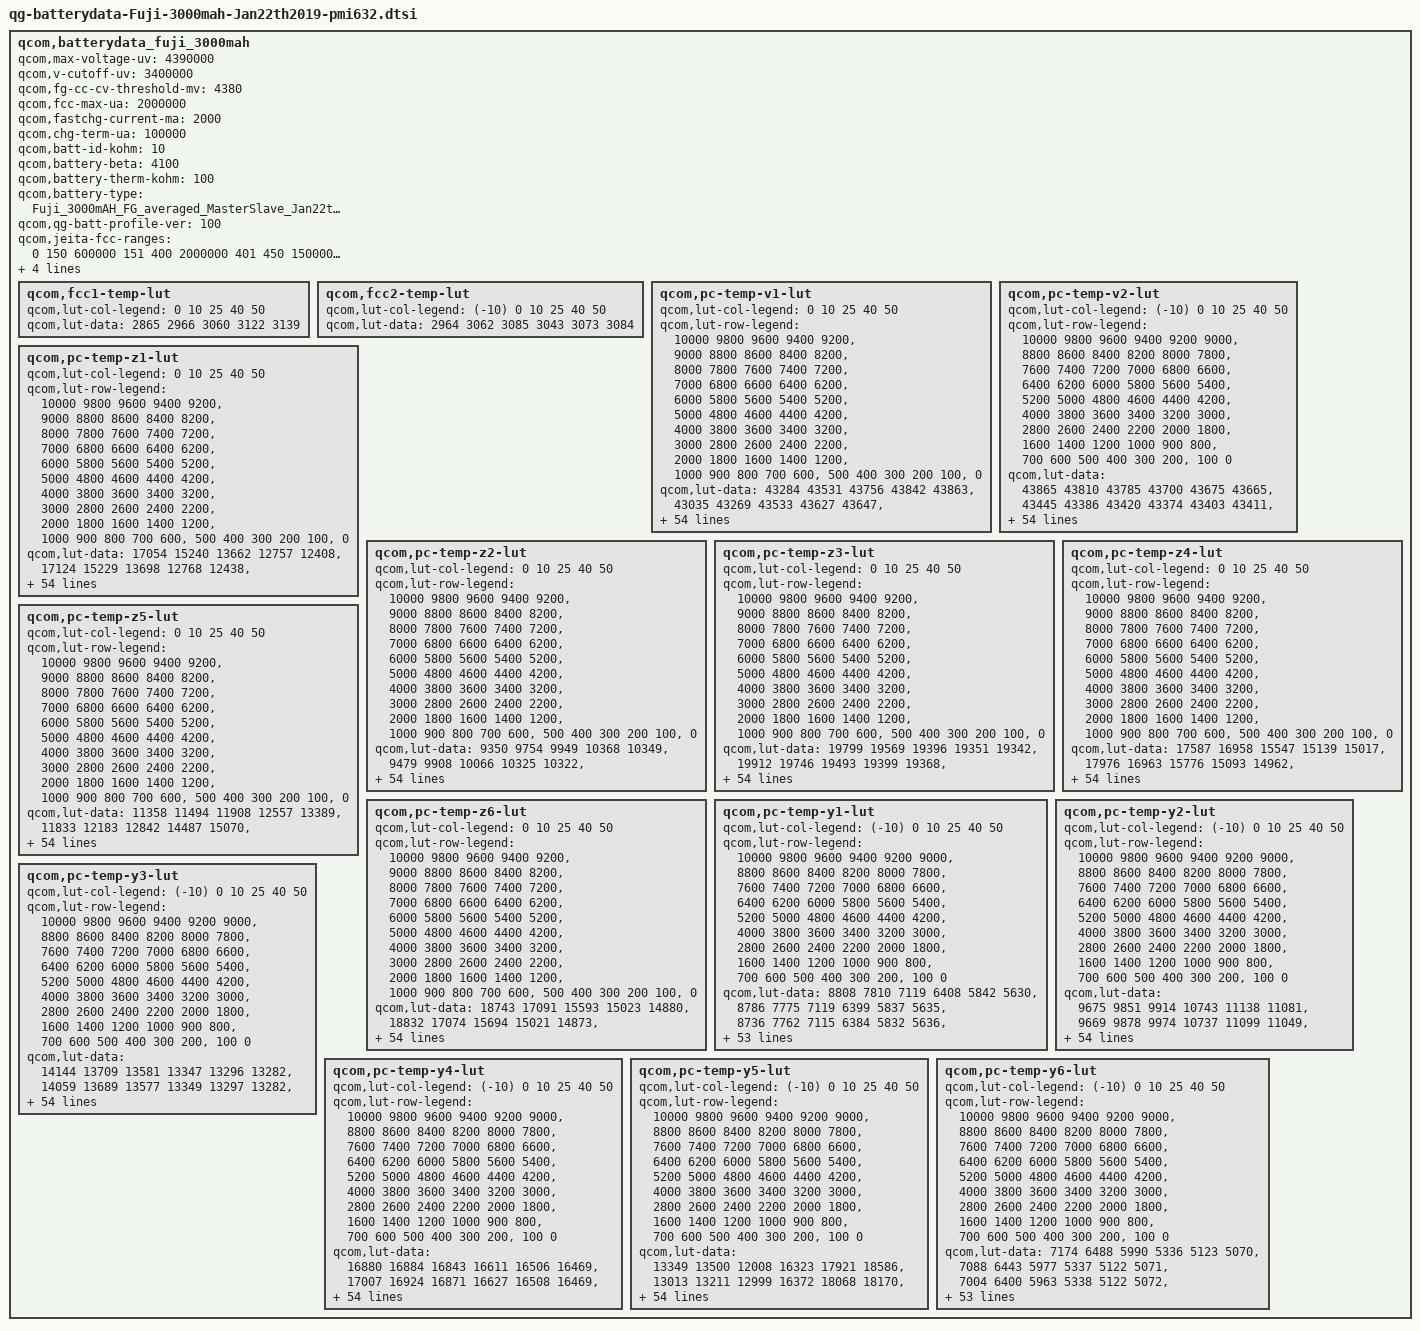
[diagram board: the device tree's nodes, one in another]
/* Copyright (c) 2018, The Linux Foundation. All rights reserved.
 *
 * This program is free software; you can redistribute it and/or modify
 * it under the terms of the GNU General Public License version 2 and
 * only version 2 as published by the Free Software Foundation.
 *
 * This program is distributed in the hope that it will be useful,
 * but WITHOUT ANY WARRANTY; without even the implied warranty of
 * MERCHANTABILITY or FITNESS FOR A PARTICULAR PURPOSE.  See the
 * GNU General Public License for more details.
 */
//<--[FairPhone][Charging][JasonHsing] Add battery parameter for battery spec for charging 20181228 BEGIN --
qcom,batterydata_fuji_3000mah {
	/* 3804571_Arima_8901_Fuji_3000mAH_FG_averaged_MasterSlave_Jan22th2019 */
	qcom,max-voltage-uv = <4390000>;
	qcom,v-cutoff-uv = <3400000>;
	qcom,fg-cc-cv-threshold-mv = <4380>;

	qcom,fcc-max-ua = <2000000>;
	qcom,fastchg-current-ma = <2000>;
	qcom,chg-term-ua = <100000>;

//<--[FairPhone][Charging][JasonHsing] Battery ID change to 10 kohm 20181107 BEGIN --
#if 1
	qcom,batt-id-kohm = <10>;
#else
	qcom,batt-id-kohm = <82>;
#endif
//-->[FairPhone][Charging][JasonHsing] Battery ID change to 10 kohm 20181107 END --
	qcom,battery-beta = <4100>;
	qcom,battery-therm-kohm = <100>;
	qcom,battery-type =
		"Fuji_3000mAH_FG_averaged_MasterSlave_Jan22th2019";
	qcom,qg-batt-profile-ver = <100>;

//<2019/08/19-JessicaTseng, Modify FCC is 1500mA at 40 ~ 45 degree, 500mA at 45 ~ 60 degree.
//<--[FairPhone][Charging][JasonHsing] Fix SW jeita is not correct 20190716 BEGIN --
	qcom,jeita-fcc-ranges = <0   150   600000
				 151 400  2000000
				 401 450  1500000
				 451 550  1000000
				 551 600  0>;
	qcom,jeita-fv-ranges =  <0   150  4400000
				 151 400  4400000
				 401 450  4400000
				 451 550  4100000
				 551 600  3300000>;
//-->[FairPhone][Charging][JasonHsing] Fix SW jeita is not correct 20190716 END --
//>2019/08/19-JessicaTseng

//-->[FairPhone][Charging][JasonHsing] Add battery parameter for battery spec for charging 20181228 END --
//<--[FairPhone][Charging][JasonHsing] Setting jeita cold/cool/warm/hot threshold for charging 20190115 BEGIN --
	/* COOL = 15 DegC, WARM = 45 DegC */
	qcom,jeita-soft-thresholds = <0x44FF 0x2204>;
	/* COLD = 0 DegC, HOT = 55 DegC */
	qcom,jeita-hard-thresholds = <0x5675 0x1987>;
//-->[FairPhone][Charging][JasonHsing] Setting jeita cold/cool/warm/hot threshold for charging 20190115 END --

	qcom,fcc1-temp-lut {
		qcom,lut-col-legend = <0 10 25 40 50>;
		qcom,lut-data = <2865 2966 3060 3122 3139>;
	};

	qcom,fcc2-temp-lut {
		qcom,lut-col-legend = <(-10) 0 10 25 40 50>;
		qcom,lut-data = <2964 3062 3085 3043 3073 3084>;
	};

	qcom,pc-temp-v1-lut {
		qcom,lut-col-legend = <0 10 25 40 50>;
		qcom,lut-row-legend = <10000 9800 9600 9400 9200>,
			<9000 8800 8600 8400 8200>,
			<8000 7800 7600 7400 7200>,
			<7000 6800 6600 6400 6200>,
			<6000 5800 5600 5400 5200>,
			<5000 4800 4600 4400 4200>,
			<4000 3800 3600 3400 3200>,
			<3000 2800 2600 2400 2200>,
			<2000 1800 1600 1400 1200>,
			<1000 900 800 700 600>,
			<500 400 300 200 100>,
			<0>;
		qcom,lut-data = <43284 43531 43756 43842 43863>,
			<43035 43269 43533 43627 43647>,
			<42788 43017 43288 43406 43431>,
			<42545 42778 43048 43178 43209>,
			<42307 42546 42811 42943 42981>,
			<42074 42313 42575 42706 42747>,
			<41845 42081 42342 42469 42511>,
			<41622 41854 42110 42233 42274>,
			<41406 41630 41881 42000 42041>,
			<41204 41411 41654 41770 41809>,
			<41011 41204 41429 41542 41580>,
			<40801 41011 41212 41319 41355>,
			<40550 40819 41007 41100 41134>,
			<40289 40612 40807 40887 40921>,
			<40063 40394 40602 40682 40712>,
			<39865 40195 40395 40484 40510>,
			<39698 40019 40206 40294 40315>,
			<39558 39864 40038 40115 40132>,
			<39432 39730 39880 39943 39960>,
			<39303 39606 39725 39775 39791>,
			<39169 39484 39573 39617 39628>,
			<39039 39364 39419 39446 39459>,
			<38920 39243 39268 39205 39244>,
			<38809 39118 39104 38925 38987>,
			<38706 38995 38900 38754 38801>,
			<38609 38886 38687 38657 38686>,
			<38521 38792 38545 38574 38589>,
			<38447 38703 38445 38490 38487>,
			<38383 38606 38368 38410 38392>,
			<38327 38500 38306 38331 38306>,
			<38279 38414 38255 38252 38230>,
			<38236 38348 38214 38183 38160>,
			<38195 38294 38182 38127 38101>,
			<38155 38248 38148 38074 38045>,
			<38115 38208 38113 38025 37991>,
			<38070 38172 38076 37979 37937>,
			<38019 38140 38037 37930 37877>,
			<37980 38104 37995 37880 37810>,
			<37979 38053 37936 37818 37735>,
			<37989 37979 37842 37732 37651>,
			<37954 37885 37727 37624 37556>,
			<37853 37750 37609 37504 37443>,
			<37727 37596 37477 37366 37307>,
			<37570 37437 37322 37204 37147>,
			<37405 37295 37175 37057 36996>,
			<37275 37197 37079 36975 36913>,
			<37228 37152 37054 36955 36894>,
			<37187 37128 37032 36940 36880>,
			<37145 37096 37015 36923 36865>,
			<37083 37054 36984 36882 36824>,
			<36912 36900 36821 36673 36613>,
			<36504 36491 36441 36265 36205>,
			<35936 35949 35916 35716 35662>,
			<35181 35220 35209 34971 34929>,
			<33991 34089 34155 33851 33829>,
			<30000 30000 30000 30000 30000>;
	};

	qcom,pc-temp-v2-lut {
		qcom,lut-col-legend = <(-10) 0 10 25 40 50>;
		qcom,lut-row-legend = <10000 9800 9600 9400 9200 9000>,
			<8800 8600 8400 8200 8000 7800>,
			<7600 7400 7200 7000 6800 6600>,
			<6400 6200 6000 5800 5600 5400>,
			<5200 5000 4800 4600 4400 4200>,
			<4000 3800 3600 3400 3200 3000>,
			<2800 2600 2400 2200 2000 1800>,
			<1600 1400 1200 1000 900 800>,
			<700 600 500 400 300 200>,
			<100 0>;
		qcom,lut-data = <43865 43810 43785 43700 43675 43665>,
			<43445 43386 43420 43374 43403 43411>,
			<43061 43012 43087 43074 43142 43164>,
			<42715 42699 42792 42806 42895 42924>,
			<42400 42432 42528 42566 42661 42693>,
			<42116 42193 42275 42331 42430 42462>,
			<41856 41988 42029 42097 42198 42230>,
			<41623 41789 41786 41867 41968 41999>,
			<41426 41533 41519 41640 41739 41772>,
			<41256 41231 41242 41417 41512 41547>,
			<41083 41027 41055 41200 41291 41325>,
			<40887 40937 40957 40990 41076 41108>,
			<40674 40843 40851 40786 40867 40894>,
			<40418 40575 40624 40587 40663 40690>,
			<40052 40115 40304 40393 40464 40490>,
			<39703 39807 40049 40214 40273 40298>,
			<39484 39642 39853 40060 40089 40112>,
			<39316 39494 39659 39905 39915 39934>,
			<39146 39312 39445 39713 39757 39769>,
			<38969 39122 39229 39495 39604 39604>,
			<38801 38939 39031 39277 39409 39409>,
			<38645 38757 38848 39052 39154 39173>,
			<38500 38588 38674 38846 38924 38957>,
			<38379 38430 38503 38682 38751 38779>,
			<38282 38292 38345 38540 38606 38627>,
			<38200 38194 38221 38416 38483 38503>,
			<38126 38119 38122 38305 38376 38396>,
			<38060 38053 38050 38204 38281 38299>,
			<37997 37990 37995 38111 38195 38209>,
			<37934 37932 37946 38024 38116 38126>,
			<37873 37874 37900 37951 38038 38051>,
			<37814 37818 37859 37886 37961 37982>,
			<37757 37761 37815 37830 37889 37918>,
			<37698 37702 37770 37782 37823 37860>,
			<37639 37642 37721 37740 37760 37795>,
			<37579 37580 37669 37699 37692 37701>,
			<37519 37515 37611 37658 37622 37590>,
			<37460 37451 37548 37613 37546 37491>,
			<37397 37386 37478 37553 37467 37405>,
			<37332 37321 37398 37482 37384 37323>,
			<37263 37258 37299 37394 37300 37242>,
			<37188 37195 37188 37281 37202 37148>,
			<37104 37132 37077 37156 37078 37026>,
			<37008 37062 36981 37012 36935 36888>,
			<36897 36973 36906 36861 36810 36769>,
			<36753 36865 36836 36801 36780 36742>,
			<36665 36812 36803 36782 36767 36730>,
			<36551 36742 36771 36769 36750 36716>,
			<36416 36637 36719 36736 36721 36684>,
			<36223 36466 36610 36679 36634 36594>,
			<35963 36186 36375 36502 36349 36303>,
			<35623 35770 35979 36106 35895 35839>,
			<35148 35191 35403 35552 35295 35244>,
			<34444 34358 34580 34813 34488 34441>,
			<33312 33033 33293 33745 33316 33316>,
			<31012 30090 30748 31936 31165 30645>;
	};

	qcom,pc-temp-z1-lut {
		qcom,lut-col-legend = <0 10 25 40 50>;
		qcom,lut-row-legend = <10000 9800 9600 9400 9200>,
			<9000 8800 8600 8400 8200>,
			<8000 7800 7600 7400 7200>,
			<7000 6800 6600 6400 6200>,
			<6000 5800 5600 5400 5200>,
			<5000 4800 4600 4400 4200>,
			<4000 3800 3600 3400 3200>,
			<3000 2800 2600 2400 2200>,
			<2000 1800 1600 1400 1200>,
			<1000 900 800 700 600>,
			<500 400 300 200 100>,
			<0>;
		qcom,lut-data = <17054 15240 13662 12757 12408>,
			<17124 15229 13698 12768 12438>,
			<17016 15219 13668 12726 12417>,
			<16914 15183 13617 12701 12397>,
			<16838 15155 13583 12668 12382>,
			<16744 15143 13558 12638 12370>,
			<16640 15093 13528 12609 12359>,
			<16529 15012 13482 12590 12352>,
			<16427 14931 13442 12580 12348>,
			<16342 14856 13422 12574 12346>,
			<16264 14788 13406 12572 12345>,
			<16170 14704 13400 12569 12346>,
			<16019 14604 13414 12569 12347>,
			<15850 14481 13431 12570 12349>,
			<15738 14362 13422 12573 12352>,
			<15657 14330 13401 12574 12355>,
			<15581 14346 13398 12577 12358>,
			<15496 14373 13416 12581 12363>,
			<15420 14400 13430 12589 12368>,
			<15369 14430 13439 12596 12373>,
			<15329 14464 13455 12602 12378>,
			<15295 14511 13473 12609 12383>,
			<15264 14559 13503 12615 12389>,
			<15235 14602 13523 12621 12394>,
			<15225 14639 13527 12629 12400>,
			<15259 14663 13531 12640 12409>,
			<15299 14691 13544 12651 12418>,
			<15307 14724 13572 12661 12427>,
			<15298 14758 13586 12672 12435>,
			<15297 14796 13584 12682 12444>,
			<15325 14832 13582 12692 12454>,
			<15372 14866 13587 12702 12463>,
			<15403 14897 13616 12713 12472>,
			<15419 14941 13638 12726 12481>,
			<15435 15005 13645 12741 12490>,
			<15466 15037 13651 12757 12499>,
			<15533 15047 13666 12768 12508>,
			<15611 15059 13689 12775 12517>,
			<15713 15086 13712 12783 12525>,
			<15815 15129 13745 12797 12534>,
			<15877 15157 13778 12814 12544>,
			<15962 15156 13793 12827 12553>,
			<16018 15159 13807 12840 12562>,
			<16054 15244 13834 12856 12571>,
			<16139 15219 13861 12870 12581>,
			<16155 15207 13872 12888 12593>,
			<16128 15182 13833 12892 12600>,
			<16123 15232 13881 12902 12605>,
			<16064 15224 13854 12918 12610>,
			<16159 15224 13885 12928 12621>,
			<16206 15263 13908 12947 12632>,
			<16240 15262 13928 12953 12645>,
			<16304 15324 13949 12982 12663>,
			<16264 15364 13995 13019 12688>,
			<16264 15364 13995 13019 12688>,
			<16264 15364 13995 13019 12688>;
	};

	qcom,pc-temp-z2-lut {
		qcom,lut-col-legend = <0 10 25 40 50>;
		qcom,lut-row-legend = <10000 9800 9600 9400 9200>,
			<9000 8800 8600 8400 8200>,
			<8000 7800 7600 7400 7200>,
			<7000 6800 6600 6400 6200>,
			<6000 5800 5600 5400 5200>,
			<5000 4800 4600 4400 4200>,
			<4000 3800 3600 3400 3200>,
			<3000 2800 2600 2400 2200>,
			<2000 1800 1600 1400 1200>,
			<1000 900 800 700 600>,
			<500 400 300 200 100>,
			<0>;
		qcom,lut-data = <9350 9754 9949 10368 10349>,
			<9479 9908 10066 10325 10322>,
			<9559 9989 10154 10384 10464>,
			<9616 10006 10169 10359 10507>,
			<9660 10015 10160 10338 10448>,
			<9687 10030 10125 10312 10406>,
			<9695 10019 10096 10277 10379>,
			<9698 9989 10087 10254 10355>,
			<9700 9988 10091 10245 10335>,
			<9700 9993 10097 10241 10323>,
			<9699 9995 10102 10249 10325>,
			<9700 9986 10105 10264 10316>,
			<9712 9970 10090 10274 10298>,
			<9728 9962 10066 10285 10271>,
			<9739 9951 10067 10291 10260>,
			<9746 9935 10080 10269 10272>,
			<9748 9920 10092 10244 10286>,
			<9730 9905 10101 10251 10287>,
			<9701 9875 10113 10278 10301>,
			<9681 9840 10131 10302 10317>,
			<9655 9822 10159 10343 10330>,
			<9630 9813 10191 10378 10342>,
			<9617 9809 10233 10329 10330>,
			<9607 9828 10258 10225 10299>,
			<9604 9858 10240 10187 10291>,
			<9606 9862 10214 10182 10339>,
			<9607 9842 10211 10192 10409>,
			<9605 9825 10202 10281 10482>,
			<9593 9853 10196 10410 10548>,
			<9580 9988 10211 10450 10534>,
			<9575 10068 10236 10463 10429>,
			<9569 10061 10257 10460 10363>,
			<9553 10046 10276 10423 10353>,
			<9505 10042 10293 10391 10352>,
			<9460 10041 10308 10400 10381>,
			<9448 10041 10319 10429 10460>,
			<9448 10044 10324 10456 10531>,
			<9447 10049 10328 10483 10597>,
			<9421 10058 10333 10510 10636>,
			<9375 10076 10351 10539 10644>,
			<9330 10095 10369 10563 10643>,
			<9274 10114 10376 10558 10608>,
			<9238 10135 10380 10536 10508>,
			<9214 10156 10366 10535 10521>,
			<9259 10180 10386 10536 10557>,
			<9240 10062 10415 10512 10526>,
			<9254 10173 10397 10455 10497>,
			<9279 9874 10392 10437 10496>,
			<9290 9778 10398 10442 10527>,
			<9293 9745 10432 10482 10608>,
			<9286 9862 10424 10564 10552>,
			<9238 10014 10422 10498 10451>,
			<9256 9882 10280 10429 10345>,
			<9197 9773 10194 10309 10327>,
			<9197 9773 10194 10309 10327>,
			<9197 9773 10194 10309 10327>;
	};

	qcom,pc-temp-z3-lut {
		qcom,lut-col-legend = <0 10 25 40 50>;
		qcom,lut-row-legend = <10000 9800 9600 9400 9200>,
			<9000 8800 8600 8400 8200>,
			<8000 7800 7600 7400 7200>,
			<7000 6800 6600 6400 6200>,
			<6000 5800 5600 5400 5200>,
			<5000 4800 4600 4400 4200>,
			<4000 3800 3600 3400 3200>,
			<3000 2800 2600 2400 2200>,
			<2000 1800 1600 1400 1200>,
			<1000 900 800 700 600>,
			<500 400 300 200 100>,
			<0>;
		qcom,lut-data = <19799 19569 19396 19351 19342>,
			<19912 19746 19493 19399 19368>,
			<19966 19815 19586 19441 19391>,
			<19983 19811 19632 19464 19415>,
			<19985 19772 19643 19476 19423>,
			<19980 19735 19646 19481 19427>,
			<19971 19703 19645 19484 19429>,
			<19953 19677 19638 19484 19428>,
			<19929 19656 19629 19474 19421>,
			<19904 19637 19622 19459 19409>,
			<19879 19613 19614 19447 19401>,
			<19855 19584 19603 19437 19392>,
			<19832 19555 19583 19429 19384>,
			<19811 19527 19565 19424 19376>,
			<19797 19502 19554 19418 19371>,
			<19788 19486 19545 19407 19369>,
			<19778 19477 19534 19397 19367>,
			<19759 19468 19520 19394 19363>,
			<19734 19452 19507 19392 19356>,
			<19712 19435 19500 19392 19352>,
			<19692 19424 19494 19394 19354>,
			<19675 19418 19494 19397 19356>,
			<19660 19414 19497 19400 19356>,
			<19647 19456 19499 19403 19354>,
			<19637 19525 19503 19401 19351>,
			<19629 19538 19508 19385 19344>,
			<19622 19532 19509 19374 19339>,
			<19614 19525 19505 19375 19359>,
			<19605 19550 19502 19379 19396>,
			<19596 19670 19499 19394 19406>,
			<19586 19740 19497 19431 19405>,
			<19574 19731 19496 19445 19403>,
			<19563 19717 19495 19440 19396>,
			<19552 19703 19494 19431 19385>,
			<19539 19688 19496 19423 19378>,
			<19523 19671 19498 19413 19371>,
			<19505 19648 19497 19408 19369>,
			<19488 19627 19493 19406 19371>,
			<19457 19610 19490 19404 19373>,
			<19409 19596 19488 19402 19373>,
			<19364 19591 19485 19401 19371>,
			<19319 19593 19484 19398 19367>,
			<19308 19595 19482 19395 19360>,
			<19312 19583 19473 19395 19361>,
			<19289 19511 19455 19391 19362>,
			<19288 19392 19434 19372 19348>,
			<19287 19411 19424 19366 19342>,
			<19283 19309 19418 19359 19339>,
			<19281 19283 19366 19356 19334>,
			<19281 19281 19345 19353 19329>,
			<19281 19311 19408 19343 19338>,
			<19288 19382 19391 19345 19344>,
			<19284 19387 19369 19346 19352>,
			<19293 19386 19360 19355 19342>,
			<19293 19386 19360 19355 19342>,
			<19293 19386 19360 19355 19342>;
	};

	qcom,pc-temp-z4-lut {
		qcom,lut-col-legend = <0 10 25 40 50>;
		qcom,lut-row-legend = <10000 9800 9600 9400 9200>,
			<9000 8800 8600 8400 8200>,
			<8000 7800 7600 7400 7200>,
			<7000 6800 6600 6400 6200>,
			<6000 5800 5600 5400 5200>,
			<5000 4800 4600 4400 4200>,
			<4000 3800 3600 3400 3200>,
			<3000 2800 2600 2400 2200>,
			<2000 1800 1600 1400 1200>,
			<1000 900 800 700 600>,
			<500 400 300 200 100>,
			<0>;
		qcom,lut-data = <17587 16958 15547 15139 15017>,
			<17976 16963 15776 15093 14962>,
			<17856 16883 15807 15147 14959>,
			<17670 16658 15582 15132 14987>,
			<17371 16377 15400 15029 14926>,
			<17004 16165 15259 14955 14873>,
			<16727 15984 15149 14898 14833>,
			<16521 15829 15064 14854 14802>,
			<16352 15706 14994 14820 14782>,
			<16206 15607 14932 14796 14767>,
			<16076 15526 14876 14782 14755>,
			<15991 15453 14840 14772 14747>,
			<15948 15394 14819 14761 14740>,
			<15916 15360 14805 14747 14732>,
			<15878 15335 14797 14737 14722>,
			<15812 15316 14791 14732 14711>,
			<15741 15300 14784 14728 14699>,
			<15679 15285 14769 14720 14691>,
			<15628 15271 14754 14705 14684>,
			<15613 15258 14746 14699 14680>,
			<15616 15248 14740 14697 14679>,
			<15621 15240 14739 14696 14680>,
			<15628 15229 14743 14759 14721>,
			<15635 15172 14751 14896 14839>,
			<15641 15093 14811 14935 14887>,
			<15651 15073 14906 14927 14882>,
			<15665 15073 14932 14916 14872>,
			<15674 15071 14939 14897 14836>,
			<15678 15038 14941 14868 14777>,
			<15680 14913 14928 14830 14746>,
			<15677 14839 14904 14778 14728>,
			<15671 14839 14881 14751 14717>,
			<15668 14839 14855 14743 14709>,
			<15665 14837 14830 14739 14705>,
			<15662 14828 14808 14740 14706>,
			<15662 14818 14790 14743 14712>,
			<15662 14807 14776 14747 14721>,
			<15653 14796 14764 14750 14737>,
			<15602 14787 14762 14754 14748>,
			<15521 14779 14776 14760 14747>,
			<15466 14774 14789 14764 14743>,
			<15431 14773 14783 14761 14737>,
			<15379 14772 14770 14749 14728>,
			<15284 14765 14766 14746 14727>,
			<15126 14773 14749 14739 14724>,
			<15091 14844 14714 14701 14695>,
			<15083 14814 14704 14690 14684>,
			<15073 14915 14690 14674 14662>,
			<15060 14935 14729 14654 14644>,
			<15049 14929 14743 14656 14648>,
			<15047 14898 14697 14703 14670>,
			<15089 14864 14750 14712 14672>,
			<15142 14893 14793 14714 14664>,
			<15193 14919 14820 14707 14678>,
			<15193 14919 14820 14707 14678>,
			<15193 14919 14820 14707 14678>;
	};

	qcom,pc-temp-z5-lut {
		qcom,lut-col-legend = <0 10 25 40 50>;
		qcom,lut-row-legend = <10000 9800 9600 9400 9200>,
			<9000 8800 8600 8400 8200>,
			<8000 7800 7600 7400 7200>,
			<7000 6800 6600 6400 6200>,
			<6000 5800 5600 5400 5200>,
			<5000 4800 4600 4400 4200>,
			<4000 3800 3600 3400 3200>,
			<3000 2800 2600 2400 2200>,
			<2000 1800 1600 1400 1200>,
			<1000 900 800 700 600>,
			<500 400 300 200 100>,
			<0>;
		qcom,lut-data = <11358 11494 11908 12557 13389>,
			<11833 12183 12842 14487 15070>,
			<12405 12614 13565 15212 16202>,
			<13059 12845 14214 15154 15974>,
			<13839 13016 14733 15844 16391>,
			<14725 13243 15142 16503 17010>,
			<15596 13561 15530 17246 17748>,
			<16428 13923 15943 17791 18190>,
			<17232 14315 16465 18116 18220>,
			<18038 14676 17422 18276 18181>,
			<18865 14865 18877 18272 18221>,
			<19674 14984 19625 18249 18128>,
			<20431 15072 19727 18334 17870>,
			<21130 15054 19828 18929 17679>,
			<21810 14893 20358 19394 17847>,
			<22506 14672 21207 19043 18615>,
			<23103 14352 21538 18592 19519>,
			<23615 13980 21561 18936 19805>,
			<24007 13586 21664 20345 19853>,
			<24079 13189 22550 21969 20033>,
			<23879 12900 24359 24356 21912>,
			<23551 12671 26666 26933 24174>,
			<23128 12532 29984 28811 24236>,
			<22573 16009 33223 30302 22786>,
			<22055 21616 36917 29852 20806>,
			<21614 22839 40896 23931 17498>,
			<21164 22782 41274 18905 15329>,
			<20626 22748 37726 17548 16139>,
			<19994 24693 34208 16813 18506>,
			<19350 32731 32197 17946 20729>,
			<18718 37419 30660 22928 22860>,
			<18080 37241 29522 27156 24796>,
			<17492 36724 28389 30069 26670>,
			<16942 35950 27991 31898 28277>,
			<16419 34643 29482 32339 29267>,
			<15905 32897 31269 32587 29981>,
			<15355 29571 32211 32574 30108>,
			<14748 26352 33439 31949 29477>,
			<13625 25160 33934 30921 28421>,
			<12198 24457 33717 28597 26596>,
			<11393 24278 33374 25720 24194>,
			<10921 27010 32613 24473 22458>,
			<10794 29096 30844 23817 21101>,
			<10850 27893 27612 23152 20368>,
			<11132 22763 26589 22273 20057>,
			<11208 13720 25644 21579 19840>,
			<11175 14905 22757 20915 19343>,
			<11126 11694 21938 20443 21124>,
			<11126 11332 15067 22031 23038>,
			<11136 11316 13648 21640 21325>,
			<11203 11811 21336 16010 17501>,
			<11383 13311 15695 14689 17028>,
			<11284 12864 13476 14307 17977>,
			<11138 12491 12651 14501 15692>,
			<11138 12491 12651 14501 15692>,
			<11138 12491 12651 14501 15692>;
	};

	qcom,pc-temp-z6-lut {
		qcom,lut-col-legend = <0 10 25 40 50>;
		qcom,lut-row-legend = <10000 9800 9600 9400 9200>,
			<9000 8800 8600 8400 8200>,
			<8000 7800 7600 7400 7200>,
			<7000 6800 6600 6400 6200>,
			<6000 5800 5600 5400 5200>,
			<5000 4800 4600 4400 4200>,
			<4000 3800 3600 3400 3200>,
			<3000 2800 2600 2400 2200>,
			<2000 1800 1600 1400 1200>,
			<1000 900 800 700 600>,
			<500 400 300 200 100>,
			<0>;
		qcom,lut-data = <18743 17091 15593 15023 14880>,
			<18832 17074 15694 15021 14873>,
			<18667 17018 15717 15055 14880>,
			<18442 16858 15615 15051 14899>,
			<18182 16642 15523 15006 14876>,
			<17900 16469 15442 14972 14854>,
			<17667 16323 15372 14945 14837>,
			<17477 16198 15314 14920 14821>,
			<17311 16093 15265 14896 14807>,
			<17163 16004 15224 14877 14794>,
			<17028 15920 15186 14864 14785>,
			<16900 15837 15158 14853 14777>,
			<16781 15757 15140 14844 14769>,
			<16675 15682 15125 14836 14761>,
			<16585 15617 15114 14828 14754>,
			<16505 15585 15104 14820 14748>,
			<16434 15572 15094 14813 14743>,
			<16368 15564 15082 14807 14737>,
			<16311 15560 15073 14802 14731>,
			<16274 15557 15071 14800 14728>,
			<16252 15557 15069 14801 14729>,
			<16234 15561 15069 14804 14732>,
			<16218 15568 15075 14834 14752>,
			<16204 15580 15086 14895 14802>,
			<16195 15595 15118 14912 14821>,
			<16195 15605 15163 14904 14818>,
			<16200 15611 15177 14894 14813>,
			<16204 15619 15181 14886 14809>,
			<16206 15631 15183 14880 14805>,
			<16209 15650 15178 14876 14800>,
			<16213 15665 15171 14875 14794>,
			<16218 15672 15165 14872 14788>,
			<16222 15677 15156 14868 14781>,
			<16226 15679 15150 14864 14776>,
			<16231 15679 15146 14862 14775>,
			<16239 15678 15144 14861 14776>,
			<16249 15673 15143 14861 14778>,
			<16254 15669 15144 14863 14787>,
			<16253 15670 15145 14866 14794>,
			<16249 15674 15157 14871 14794>,
			<16257 15680 15169 14875 14794>,
			<16286 15693 15172 14875 14791>,
			<16316 15704 15173 14872 14786>,
			<16342 15708 15173 14873 14787>,
			<16325 15691 15169 14872 14788>,
			<16317 15673 15152 14851 14771>,
			<16313 15670 15145 14844 14764>,
			<16314 15661 15139 14835 14754>,
			<16312 15666 15131 14827 14744>,
			<16314 15671 15133 14830 14745>,
			<16332 15687 15154 14849 14762>,
			<16363 15720 15177 14859 14770>,
			<16400 15752 15199 14867 14775>,
			<16456 15793 15224 14878 14780>,
			<16456 15793 15224 14878 14780>,
			<16456 15793 15224 14878 14780>;
	};

	qcom,pc-temp-y1-lut {
		qcom,lut-col-legend = <(-10) 0 10 25 40 50>;
		qcom,lut-row-legend = <10000 9800 9600 9400 9200 9000>,
			<8800 8600 8400 8200 8000 7800>,
			<7600 7400 7200 7000 6800 6600>,
			<6400 6200 6000 5800 5600 5400>,
			<5200 5000 4800 4600 4400 4200>,
			<4000 3800 3600 3400 3200 3000>,
			<2800 2600 2400 2200 2000 1800>,
			<1600 1400 1200 1000 900 800>,
			<700 600 500 400 300 200>,
			<100 0>;
		qcom,lut-data = <8808 7810 7119 6408 5842 5630>,
			<8786 7775 7119 6399 5837 5635>,
			<8736 7762 7115 6384 5832 5636>,
			<8678 7760 7110 6366 5827 5636>,
			<8629 7765 7105 6351 5820 5634>,
			<8607 7767 7104 6346 5814 5631>,
			<8601 7778 7101 6343 5808 5626>,
			<8591 7794 7099 6340 5801 5619>,
			<8582 7787 7102 6338 5795 5615>,
			<8573 7757 7116 6335 5790 5611>,
			<8570 7745 7124 6331 5785 5608>,
			<8624 7765 7127 6328 5779 5606>,
			<8727 7788 7126 6326 5774 5605>,
			<8752 7789 7127 6327 5770 5604>,
			<8709 7780 7131 6333 5768 5603>,
			<8675 7786 7134 6341 5767 5603>,
			<8674 7825 7137 6350 5771 5603>,
			<8678 7854 7137 6359 5774 5605>,
			<8683 7852 7147 6363 5774 5607>,
			<8693 7848 7161 6366 5773 5609>,
			<8706 7850 7165 6372 5774 5612>,
			<8744 7872 7164 6387 5778 5614>,
			<8799 7893 7165 6399 5784 5617>,
			<8812 7904 7178 6400 5791 5621>,
			<8806 7914 7197 6400 5800 5626>,
			<8795 7914 7204 6407 5807 5630>,
			<8773 7885 7208 6428 5812 5636>,
			<8743 7863 7210 6443 5819 5641>,
			<8735 7872 7220 6445 5827 5646>,
			<8759 7886 7233 6445 5834 5652>,
			<8772 7888 7234 6446 5843 5659>,
			<8759 7882 7226 6449 5852 5665>,
			<8766 7881 7224 6454 5862 5672>,
			<8792 7916 7232 6468 5871 5679>,
			<8813 7964 7241 6486 5880 5686>,
			<8815 7988 7255 6492 5888 5692>,
			<8814 8004 7277 6497 5894 5697>,
			<8836 8004 7284 6502 5901 5702>,
			<8866 7958 7264 6515 5912 5708>,
			<8906 7919 7248 6530 5925 5714>,
			<8961 7936 7272 6538 5941 5722>,
			<8999 7955 7306 6561 5956 5731>,
			<9030 7948 7304 6572 5971 5741>,
			<9138 7971 7313 6570 5991 5752>,
			<9293 8063 7376 6564 6002 5762>,
			<9280 8096 7390 6587 6025 5773>,
			<9284 8110 7390 6636 6033 5780>,
			<9320 8108 7371 6593 6049 5787>,
			<9330 8116 7400 6614 6059 5790>,
			<9393 8172 7426 6617 6073 5796>,
			<9703 8314 7410 6624 6079 5798>,
			<9758 8346 7470 6622 6098 5814>,
			<9705 8401 7565 6635 6133 5835>,
			<10044 8597 7580 6686 6162 5853>,
			<10044 8597 7580 6686 6162 5853>,
			<10044 8597 7580 6686 6162 5853>;
	};

	qcom,pc-temp-y2-lut {
		qcom,lut-col-legend = <(-10) 0 10 25 40 50>;
		qcom,lut-row-legend = <10000 9800 9600 9400 9200 9000>,
			<8800 8600 8400 8200 8000 7800>,
			<7600 7400 7200 7000 6800 6600>,
			<6400 6200 6000 5800 5600 5400>,
			<5200 5000 4800 4600 4400 4200>,
			<4000 3800 3600 3400 3200 3000>,
			<2800 2600 2400 2200 2000 1800>,
			<1600 1400 1200 1000 900 800>,
			<700 600 500 400 300 200>,
			<100 0>;
		qcom,lut-data = <9675 9851 9914 10743 11138 11081>,
			<9669 9878 9974 10737 11099 11049>,
			<9666 9917 10046 10731 11053 11013>,
			<9667 9967 10118 10726 11008 10976>,
			<9670 10024 10176 10721 10968 10946>,
			<9677 10089 10208 10716 10940 10925>,
			<9780 10167 10219 10712 10918 10911>,
			<9972 10248 10230 10708 10901 10901>,
			<10034 10326 10320 10707 10889 10894>,
			<10038 10403 10526 10711 10878 10888>,
			<10042 10429 10594 10717 10875 10888>,
			<10180 10418 10528 10741 10888 10901>,
			<10405 10407 10470 10772 10910 10922>,
			<10410 10441 10537 10793 10939 10952>,
			<10025 10548 10688 10814 10981 10998>,
			<9694 10633 10768 10844 11028 11051>,
			<9679 10703 10805 10909 11082 11129>,
			<9679 10742 10840 10969 11141 11206>,
			<9679 10736 10890 10994 11214 11272>,
			<9677 10717 10932 11012 11286 11322>,
			<9675 10674 10922 11016 11287 11314>,
			<9674 10440 10844 11003 11197 11231>,
			<9672 10221 10781 10994 11134 11160>,
			<9670 10009 10759 11001 11138 11131>,
			<9669 9764 10742 11020 11147 11115>,
			<9668 9717 10681 11032 11159 11129>,
			<9667 9704 10412 11038 11174 11163>,
			<9667 9696 10242 11039 11192 11197>,
			<9666 9690 10281 11029 11245 11226>,
			<9666 9685 10329 11015 11312 11253>,
			<9665 9681 10171 11007 11347 11291>,
			<9664 9676 9906 10994 11376 11370>,
			<9664 9673 9790 10983 11380 11454>,
			<9663 9671 9739 10978 11359 11538>,
			<9663 9669 9708 10974 11332 11581>,
			<9662 9668 9690 10971 11303 11512>,
			<9662 9666 9679 10963 11266 11359>,
			<9661 9665 9674 10949 11229 11276>,
			<9661 9664 9670 10923 11193 11241>,
			<9660 9663 9668 10883 11153 11227>,
			<9659 9662 9666 10838 11111 11226>,
			<9658 9661 9665 10778 11067 11210>,
			<9656 9661 9664 10708 11026 11160>,
			<9655 9660 9662 10622 10943 11138>,
			<9654 9659 9662 10228 10911 11078>,
			<9653 9658 9660 10125 10831 10967>,
			<9653 9657 9659 10114 10830 10950>,
			<9653 9657 9659 10273 10823 11000>,
			<9652 9656 9658 10052 10816 10977>,
			<9651 9655 9658 10003 10819 10980>,
			<9650 9653 9657 9927 10781 10944>,
			<9650 9652 9656 9774 10694 10866>,
			<9649 9650 9654 9711 10638 10811>,
			<9648 9648 9651 9680 10579 10795>,
			<9648 9648 9651 9680 10579 10795>,
			<9648 9648 9651 9680 10579 10795>;
	};

	qcom,pc-temp-y3-lut {
		qcom,lut-col-legend = <(-10) 0 10 25 40 50>;
		qcom,lut-row-legend = <10000 9800 9600 9400 9200 9000>,
			<8800 8600 8400 8200 8000 7800>,
			<7600 7400 7200 7000 6800 6600>,
			<6400 6200 6000 5800 5600 5400>,
			<5200 5000 4800 4600 4400 4200>,
			<4000 3800 3600 3400 3200 3000>,
			<2800 2600 2400 2200 2000 1800>,
			<1600 1400 1200 1000 900 800>,
			<700 600 500 400 300 200>,
			<100 0>;
		qcom,lut-data = <14144 13709 13581 13347 13296 13282>,
			<14059 13689 13577 13349 13297 13282>,
			<13977 13665 13573 13351 13298 13283>,
			<13900 13641 13566 13353 13299 13284>,
			<13833 13622 13559 13355 13301 13285>,
			<13778 13611 13551 13357 13302 13286>,
			<13735 13607 13542 13359 13304 13287>,
			<13700 13604 13531 13360 13306 13289>,
			<13663 13576 13516 13360 13306 13290>,
			<13615 13504 13494 13359 13305 13292>,
			<13577 13472 13473 13357 13305 13293>,
			<13559 13471 13452 13353 13308 13293>,
			<13546 13471 13439 13349 13311 13294>,
			<13545 13467 13441 13347 13311 13297>,
			<13547 13457 13444 13346 13310 13301>,
			<13549 13448 13443 13345 13308 13302>,
			<13548 13440 13428 13347 13305 13301>,
			<13545 13432 13411 13349 13303 13300>,
			<13545 13423 13398 13348 13304 13298>,
			<13546 13414 13385 13342 13306 13294>,
			<13548 13407 13375 13337 13305 13291>,
			<13543 13401 13365 13331 13300 13288>,
			<13530 13397 13359 13326 13296 13285>,
			<13524 13394 13357 13323 13294 13283>,
			<13527 13393 13355 13320 13293 13282>,
			<13532 13396 13344 13318 13292 13282>,
			<13542 13405 13313 13315 13291 13281>,
			<13563 13412 13299 13313 13290 13281>,
			<13584 13417 13311 13314 13292 13281>,
			<13601 13422 13330 13315 13293 13281>,
			<13619 13428 13342 13315 13294 13282>,
			<13646 13438 13352 13315 13294 13282>,
			<13681 13451 13363 13316 13293 13283>,
			<13714 13471 13379 13316 13292 13285>,
			<13744 13493 13393 13317 13291 13287>,
			<13776 13513 13404 13318 13291 13286>,
			<13808 13534 13413 13320 13291 13282>,
			<13840 13557 13426 13322 13291 13280>,
			<13880 13581 13444 13324 13290 13280>,
			<13935 13607 13463 13327 13290 13279>,
			<14003 13634 13478 13327 13291 13280>,
			<14085 13664 13495 13326 13292 13280>,
			<14183 13700 13511 13327 13294 13280>,
			<14296 13732 13519 13329 13294 13281>,
			<14422 13708 13517 13321 13291 13281>,
			<14457 13757 13563 13325 13298 13285>,
			<14503 13801 13590 13331 13304 13289>,
			<14521 13839 13628 13342 13308 13295>,
			<14713 13901 13658 13344 13315 13298>,
			<14935 14010 13687 13353 13319 13301>,
			<15231 14155 13722 13360 13315 13297>,
			<15654 14400 13776 13376 13318 13298>,
			<16286 14815 13917 13404 13325 13302>,
			<17253 15517 14206 13445 13334 13308>,
			<17253 15517 14206 13445 13334 13308>,
			<17253 15517 14206 13445 13334 13308>;
	};

	qcom,pc-temp-y4-lut {
		qcom,lut-col-legend = <(-10) 0 10 25 40 50>;
		qcom,lut-row-legend = <10000 9800 9600 9400 9200 9000>,
			<8800 8600 8400 8200 8000 7800>,
			<7600 7400 7200 7000 6800 6600>,
			<6400 6200 6000 5800 5600 5400>,
			<5200 5000 4800 4600 4400 4200>,
			<4000 3800 3600 3400 3200 3000>,
			<2800 2600 2400 2200 2000 1800>,
			<1600 1400 1200 1000 900 800>,
			<700 600 500 400 300 200>,
			<100 0>;
		qcom,lut-data = <16880 16884 16843 16611 16506 16469>,
			<17007 16924 16871 16627 16508 16469>,
			<17093 16973 16919 16648 16510 16469>,
			<17145 17019 16971 16670 16510 16470>,
			<17172 17053 17011 16687 16510 16470>,
			<17179 17065 17025 16693 16510 16470>,
			<17149 17056 17023 16691 16508 16471>,
			<17093 17046 17018 16687 16507 16471>,
			<17094 17059 17011 16687 16508 16472>,
			<17226 17114 17000 16690 16513 16475>,
			<17333 17176 17007 16695 16518 16478>,
			<17293 17260 17141 16712 16521 16484>,
			<17204 17323 17260 16733 16525 16490>,
			<17135 17210 17179 16744 16533 16494>,
			<17035 16910 16999 16752 16549 16497>,
			<16948 16809 16929 16761 16566 16503>,
			<16928 16821 16912 16775 16589 16517>,
			<16919 16831 16893 16785 16611 16536>,
			<16904 16817 16852 16772 16634 16565>,
			<16871 16780 16801 16731 16654 16596>,
			<16843 16747 16757 16685 16645 16593>,
			<16842 16716 16720 16629 16574 16546>,
			<16845 16694 16678 16583 16515 16502>,
			<16850 16683 16617 16562 16493 16476>,
			<16865 16674 16566 16549 16480 16460>,
			<16884 16670 16562 16543 16480 16460>,
			<16890 16668 16600 16542 16487 16466>,
			<16893 16668 16626 16539 16496 16474>,
			<16898 16673 16612 16531 16505 16485>,
			<16914 16680 16593 16518 16515 16497>,
			<16931 16687 16601 16515 16520 16510>,
			<16940 16695 16621 16515 16523 16524>,
			<16946 16700 16638 16515 16526 16533>,
			<16955 16703 16653 16523 16529 16540>,
			<16968 16707 16669 16538 16531 16542>,
			<16987 16715 16686 16553 16526 16525>,
			<17010 16726 16701 16572 16512 16494>,
			<17038 16740 16707 16587 16503 16478>,
			<17075 16758 16709 16598 16496 16471>,
			<17132 16779 16708 16605 16494 16470>,
			<17202 16805 16693 16606 16500 16476>,
			<17280 16832 16672 16605 16509 16481>,
			<17371 16860 16659 16599 16511 16480>,
			<17453 16867 16656 16576 16509 16478>,
			<17499 16793 16648 16557 16478 16450>,
			<17354 16787 16668 16568 16493 16466>,
			<17325 16805 16690 16584 16507 16478>,
			<17230 16828 16716 16599 16525 16487>,
			<17314 16853 16750 16641 16543 16505>,
			<17418 16879 16774 16676 16557 16515>,
			<17579 16937 16765 16673 16529 16487>,
			<17841 17050 16758 16641 16533 16488>,
			<18286 17288 16811 16646 16553 16508>,
			<19246 17929 17050 16675 16600 16553>,
			<19246 17929 17050 16675 16600 16553>,
			<19246 17929 17050 16675 16600 16553>;
	};

	qcom,pc-temp-y5-lut {
		qcom,lut-col-legend = <(-10) 0 10 25 40 50>;
		qcom,lut-row-legend = <10000 9800 9600 9400 9200 9000>,
			<8800 8600 8400 8200 8000 7800>,
			<7600 7400 7200 7000 6800 6600>,
			<6400 6200 6000 5800 5600 5400>,
			<5200 5000 4800 4600 4400 4200>,
			<4000 3800 3600 3400 3200 3000>,
			<2800 2600 2400 2200 2000 1800>,
			<1600 1400 1200 1000 900 800>,
			<700 600 500 400 300 200>,
			<100 0>;
		qcom,lut-data = <13349 13500 12008 16323 17921 18586>,
			<13013 13211 12999 16372 18068 18170>,
			<13045 13460 14163 16440 18117 17710>,
			<13320 14144 15309 16514 18105 17265>,
			<13715 15164 16245 16584 18071 16894>,
			<14107 16431 16784 16639 18053 16652>,
			<15410 18600 17088 16695 17996 16513>,
			<17536 20511 17255 16740 17870 16387>,
			<18076 19525 16766 16676 17290 16217>,
			<17054 15658 15346 16346 15850 16011>,
			<16481 14123 14892 15892 15277 15729>,
			<19499 17492 16061 14980 15396 15204>,
			<24621 21017 17812 14144 15517 14821>,
			<25408 20858 19909 14373 15176 15053>,
			<19266 19889 22106 15510 14330 15539>,
			<14011 19657 22597 16782 13917 15522>,
			<13930 20662 22429 18272 13747 14811>,
			<14318 21567 22355 19738 13690 14376>,
			<14451 21644 22492 20874 14676 14378>,
			<14374 21674 22713 21825 16938 14452>,
			<14244 21685 22878 22222 19000 15411>,
			<13814 20618 23037 22357 21260 18677>,
			<12837 19295 23301 22430 22271 20342>,
			<12176 16786 23920 22466 21851 20137>,
			<11864 13808 23986 22484 20993 19645>,
			<11690 13424 20980 22476 20018 18847>,
			<11718 13473 14954 22064 18767 17527>,
			<11839 13487 12836 21697 18243 16702>,
			<11898 13409 13272 22531 19014 16373>,
			<11842 13290 13839 24064 20139 16235>,
			<11799 13214 13911 24209 20558 16295>,
			<11882 13197 13854 22855 20583 16587>,
			<12081 13234 13947 21466 20365 17253>,
			<12245 13308 14112 20300 20058 19153>,
			<12343 13345 14250 19299 19990 20733>,
			<12425 13241 14355 18875 20397 20809>,
			<12521 13059 14473 18615 20909 20171>,
			<12618 12937 14722 18543 20846 19319>,
			<12669 12781 15271 18808 19408 18313>,
			<12666 12638 15669 19097 17814 17411>,
			<12672 12597 15667 18859 16901 16533>,
			<12691 12631 15351 17917 16234 15888>,
			<12643 12878 14521 18213 16069 15695>,
			<12660 13276 13856 19221 16226 15964>,
			<12919 13897 13862 16001 18127 19756>,
			<13276 14032 13814 14924 17294 17122>,
			<13415 14407 13713 14773 16651 16358>,
			<13462 14550 14038 15725 15949 16993>,
			<13362 14718 14211 14276 16288 16750>,
			<12923 14999 14569 14561 17215 18436>,
			<12369 14407 14848 14966 18423 20471>,
			<11893 13109 14633 14660 19769 21365>,
			<11228 12058 13726 14484 20580 22907>,
			<10382 11039 12284 14642 21348 24120>,
			<10382 11039 12284 14642 21348 24120>,
			<10382 11039 12284 14642 21348 24120>;
	};

	qcom,pc-temp-y6-lut {
		qcom,lut-col-legend = <(-10) 0 10 25 40 50>;
		qcom,lut-row-legend = <10000 9800 9600 9400 9200 9000>,
			<8800 8600 8400 8200 8000 7800>,
			<7600 7400 7200 7000 6800 6600>,
			<6400 6200 6000 5800 5600 5400>,
			<5200 5000 4800 4600 4400 4200>,
			<4000 3800 3600 3400 3200 3000>,
			<2800 2600 2400 2200 2000 1800>,
			<1600 1400 1200 1000 900 800>,
			<700 600 500 400 300 200>,
			<100 0>;
		qcom,lut-data = <7174 6488 5990 5336 5123 5070>,
			<7088 6443 5977 5337 5122 5071>,
			<7004 6400 5963 5338 5122 5072>,
			<6926 6360 5948 5338 5122 5072>,
			<6857 6324 5931 5338 5121 5073>,
			<6801 6295 5913 5338 5121 5074>,
			<6753 6272 5893 5335 5121 5074>,
			<6715 6251 5872 5331 5120 5075>,
			<6695 6217 5847 5327 5120 5076>,
			<6680 6173 5819 5324 5120 5077>,
			<6668 6156 5812 5323 5120 5078>,
			<6655 6172 5831 5323 5122 5080>,
			<6635 6187 5849 5323 5125 5082>,
			<6610 6157 5830 5323 5128 5085>,
			<6553 6076 5788 5324 5130 5088>,
			<6504 6045 5764 5326 5134 5091>,
			<6492 6044 5753 5332 5138 5095>,
			<6487 6042 5741 5337 5143 5100>,
			<6483 6035 5724 5333 5150 5106>,
			<6479 6023 5705 5318 5157 5112>,
			<6476 6013 5690 5302 5154 5110>,
			<6474 6004 5678 5283 5130 5094>,
			<6471 5997 5668 5269 5111 5079>,
			<6471 5991 5658 5264 5104 5071>,
			<6481 5986 5652 5262 5100 5066>,
			<6497 5988 5652 5262 5100 5066>,
			<6513 6004 5658 5264 5102 5068>,
			<6530 6022 5667 5266 5105 5070>,
			<6549 6037 5688 5268 5110 5074>,
			<6571 6054 5714 5271 5115 5078>,
			<6596 6076 5739 5274 5118 5083>,
			<6624 6104 5768 5281 5120 5088>,
			<6656 6132 5800 5289 5122 5093>,
			<6689 6159 5834 5300 5123 5097>,
			<6723 6188 5870 5315 5124 5099>,
			<6759 6220 5907 5331 5124 5093>,
			<6795 6256 5946 5351 5121 5083>,
			<6833 6291 5985 5373 5121 5078>,
			<6885 6324 6023 5395 5121 5076>,
			<6968 6358 6057 5419 5121 5076>,
			<7077 6396 6083 5441 5126 5079>,
			<7209 6437 6107 5463 5133 5082>,
			<7380 6484 6136 5487 5140 5084>,
			<7573 6535 6166 5510 5144 5084>,
			<7769 6532 6182 5515 5136 5078>,
			<7828 6592 6243 5539 5150 5087>,
			<7890 6644 6283 5566 5161 5094>,
			<7929 6694 6329 5597 5173 5102>,
			<8177 6776 6372 5629 5187 5111>,
			<8470 6929 6419 5671 5197 5116>,
			<8868 7149 6460 5696 5190 5106>,
			<9428 7492 6523 5720 5201 5109>,
			<10244 8043 6746 5788 5225 5121>,
			<11535 8996 7213 5886 5260 5142>,
			<11535 8996 7213 5886 5260 5142>,
			<11535 8996 7213 5886 5260 5142>;
	};

};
